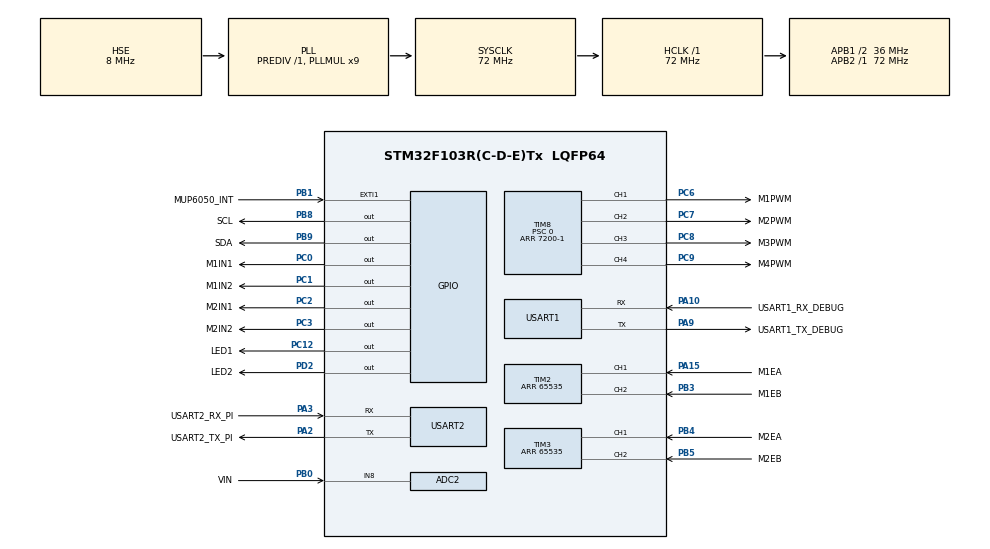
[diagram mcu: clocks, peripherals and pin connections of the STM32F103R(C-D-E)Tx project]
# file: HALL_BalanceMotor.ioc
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ADC1.Channel-0\#ChannelRegularConversion=ADC_CHANNEL_TEMPSENSOR
ADC1.NbrOfConversionFlag=1
ADC1.Rank-0\#ChannelRegularConversion=1
ADC1.SamplingTime-0\#ChannelRegularConversion=ADC_SAMPLETIME_1CYCLE_5
ADC1.master=1
ADC2.Channel-0\#ChannelRegularConversion=ADC_CHANNEL_8
ADC2.NbrOfConversionFlag=1
ADC2.Rank-0\#ChannelRegularConversion=1
ADC2.SamplingTime-0\#ChannelRegularConversion=ADC_SAMPLETIME_1CYCLE_5
Dma.Request0=USART2_RX
Dma.USART2_RX.0.Direction=DMA_PERIPH_TO_MEMORY
Dma.USART2_RX.0.Instance=DMA1_Channel6
Dma.USART2_RX.0.MemDataAlignment=DMA_MDATAALIGN_BYTE
Dma.USART2_RX.0.MemInc=DMA_MINC_ENABLE
Dma.USART2_RX.0.Mode=DMA_CIRCULAR
Dma.USART2_RX.0.PeriphDataAlignment=DMA_PDATAALIGN_BYTE
Dma.USART2_RX.0.PeriphInc=DMA_PINC_DISABLE
Dma.USART2_RX.0.Priority=DMA_PRIORITY_HIGH
FREERTOS.BinarySemaphores01=imu_sema,Dynamic,NULL;move_sema,Dynamic,NULL
FREERTOS.HEAP_NUMBER=4
FREERTOS.Tasks01=defaultTask,0,128,StartDefaultTask,Default,NULL,Dynamic,NULL,NULL;KEY,0,128,key_task,As external,NULL,Dynamic,NULL,NULL;LED,0,128,led_task,As external,NULL,Dynamic,NULL,NULL;CMD,0,128,cmd_task,As external,NULL,Dynamic,NULL,NULL;MOVE,3,128,move_task,As external,NULL,Dynamic,NULL,NULL;VIN,0,128,vin_task,As external,NULL,Dynamic,NULL,NULL;PI,0,128,pi_task,As external,NULL,Dynamic,NULL,NULL;IMU,3,128,imu_task,As external,NULL,Dynamic,NULL,NULL;OTHER,0,128,other_task,As external,NULL,Dynamic,NULL,NULL
FREERTOS.configTOTAL_HEAP_SIZE=10000
FREERTOS.configUSE_NEWLIB_REENTRANT=0
FREERTOS.configUSE_PREEMPTION=1
FREERTOS.configUSE_TRACE_FACILITY=0
Mcu.Family=STM32F1
Mcu.Name=STM32F103R(C-D-E)Tx
Mcu.Package=LQFP64
NVIC.DMA1_Channel6_IRQn=true\:5\:0\:false\:false\:true\:true\:false\:true\:true
NVIC.PriorityGroup=NVIC_PRIORITYGROUP_4
NVIC.TIM2_IRQn=true\:5\:0\:false\:false\:true\:true\:true\:true\:true
NVIC.TIM3_IRQn=true\:5\:0\:false\:false\:true\:true\:true\:true\:true
NVIC.TIM6_IRQn=true\:15\:0\:false\:false\:true\:false\:false\:true\:true
NVIC.TIM7_IRQn=true\:7\:0\:true\:false\:true\:true\:true\:true\:true
NVIC.TimeBase=TIM6_IRQn
NVIC.TimeBaseIP=TIM6
NVIC.USART1_IRQn=true\:5\:0\:false\:false\:true\:true\:true\:true\:true
NVIC.USART2_IRQn=true\:5\:0\:false\:false\:true\:true\:true\:true\:true
PA10.GPIO_Label=USART1_RX_DEBUG
PA10.Mode=Asynchronous
PA10.Signal=USART1_RX
PA13.Mode=Serial_Wire
PA13.Signal=SYS_JTMS-SWDIO
PA14.Mode=Serial_Wire
PA14.Signal=SYS_JTCK-SWCLK
PA15.GPIO_Label=M1EA
PA15.Signal=S_TIM2_CH1_ETR
PA2.GPIO_Label=USART2_TX_PI
PA2.Mode=Asynchronous
PA2.Signal=USART2_TX
PA3.GPIO_Label=USART2_RX_PI
PA3.Mode=Asynchronous
PA3.Signal=USART2_RX
PA9.GPIO_Label=USART1_TX_DEBUG
PA9.Mode=Asynchronous
PA9.Signal=USART1_TX
PB0.GPIO_Label=VIN
PB0.Signal=ADCx_IN8
PB1.GPIO_Label=MUP6050_INT
PB1.Signal=GPXTI1
PB3.GPIO_Label=M1EB
PB3.Signal=S_TIM2_CH2
PB4.GPIO_Label=M2EA
PB4.Signal=S_TIM3_CH1
PB5.GPIO_Label=M2EB
PB5.Signal=S_TIM3_CH2
PB8.GPIO_Label=SCL
PB8.GPIO_PuPd=GPIO_PULLUP
PB8.GPIO_Speed=GPIO_SPEED_FREQ_HIGH
PB8.PinState=GPIO_PIN_SET
PB8.Signal=GPIO_Output
PB9.GPIO_Label=SDA
PB9.GPIO_PuPd=GPIO_PULLUP
PB9.GPIO_Speed=GPIO_SPEED_FREQ_HIGH
PB9.PinState=GPIO_PIN_SET
PB9.Signal=GPIO_Output
PC0.GPIO_Label=M1IN1
PC0.GPIO_Speed=GPIO_SPEED_FREQ_HIGH
PC0.PinState=GPIO_PIN_RESET
PC0.Signal=GPIO_Output
PC1.GPIO_Label=M1IN2
PC1.GPIO_ModeDefaultOutputPP=GPIO_MODE_OUTPUT_PP
PC1.GPIO_PuPd=GPIO_NOPULL
PC1.GPIO_Speed=GPIO_SPEED_FREQ_HIGH
PC1.PinState=GPIO_PIN_RESET
PC1.Signal=GPIO_Output
PC12.GPIO_Label=LED1
PC12.GPIO_Speed=GPIO_SPEED_FREQ_HIGH
PC12.PinState=GPIO_PIN_SET
PC12.Signal=GPIO_Output
PC2.GPIO_Label=M2IN1
PC2.GPIO_ModeDefaultOutputPP=GPIO_MODE_OUTPUT_PP
PC2.GPIO_PuPd=GPIO_NOPULL
PC2.GPIO_Speed=GPIO_SPEED_FREQ_HIGH
PC2.PinState=GPIO_PIN_RESET
PC2.Signal=GPIO_Output
PC3.GPIO_Label=M2IN2
PC3.GPIO_ModeDefaultOutputPP=GPIO_MODE_OUTPUT_PP
PC3.GPIO_PuPd=GPIO_NOPULL
PC3.GPIO_Speed=GPIO_SPEED_FREQ_HIGH
PC3.PinState=GPIO_PIN_RESET
PC3.Signal=GPIO_Output
PC6.GPIO_Label=M1PWM
PC6.GPIO_Speed=GPIO_SPEED_FREQ_HIGH
PC6.Signal=S_TIM8_CH1
PC7.GPIO_Label=M2PWM
PC7.GPIO_Speed=GPIO_SPEED_FREQ_HIGH
PC7.Signal=S_TIM8_CH2
PC8.GPIO_Label=M3PWM
PC8.GPIO_Speed=GPIO_SPEED_FREQ_HIGH
PC8.Signal=S_TIM8_CH3
PC9.GPIO_Label=M4PWM
PC9.GPIO_Speed=GPIO_SPEED_FREQ_HIGH
PC9.Signal=S_TIM8_CH4
PD0-OSC_IN.Mode=HSE-External-Oscillator
PD0-OSC_IN.Signal=RCC_OSC_IN
PD1-OSC_OUT.Mode=HSE-External-Oscillator
PD1-OSC_OUT.Signal=RCC_OSC_OUT
PD2.GPIO_Label=LED2
PD2.GPIO_Speed=GPIO_SPEED_FREQ_HIGH
PD2.PinState=GPIO_PIN_SET
PD2.Signal=GPIO_Output
ProjectManager.HeapSize=0x200
ProjectManager.StackSize=0x400
ProjectManager.TargetToolchain=MDK-ARM V5.32
RCC.ADCPresc=RCC_ADCPCLK2_DIV6
RCC.AHBFreq_Value=72000000
RCC.APB1CLKDivider=RCC_HCLK_DIV2
RCC.APB1Freq_Value=36000000
RCC.APB1TimFreq_Value=72000000
RCC.APB2Freq_Value=72000000
RCC.APB2TimFreq_Value=72000000
RCC.HCLKFreq_Value=72000000
RCC.PLLMUL=RCC_PLL_MUL9
RCC.PLLSourceVirtual=RCC_PLLSOURCE_HSE
RCC.SYSCLKFreq_VALUE=72000000
RCC.SYSCLKSource=RCC_SYSCLKSOURCE_PLLCLK
RCC.USBFreq_Value=72000000
SH.ADCx_IN8.0=ADC2_IN8,IN8
SH.S_TIM2_CH1_ETR.0=TIM2_CH1,Encoder_Interface
SH.S_TIM2_CH2.0=TIM2_CH2,Encoder_Interface
SH.S_TIM3_CH1.0=TIM3_CH1,Encoder_Interface
SH.S_TIM3_CH2.0=TIM3_CH2,Encoder_Interface
SH.S_TIM8_CH1.0=TIM8_CH1,PWM Generation1 CH1
SH.S_TIM8_CH2.0=TIM8_CH2,PWM Generation2 CH2
SH.S_TIM8_CH3.0=TIM8_CH3,PWM Generation3 CH3
SH.S_TIM8_CH4.0=TIM8_CH4,PWM Generation4 CH4
TIM2.ClockDivision=TIM_CLOCKDIVISION_DIV1
TIM2.EncoderMode=TIM_ENCODERMODE_TI12
TIM2.IC1Filter=6
TIM2.IC1Prescaler=TIM_ICPSC_DIV1
TIM2.IC2Filter=6
TIM2.IC2Prescaler=TIM_ICPSC_DIV1
TIM2.Period=65535
TIM3.ClockDivision=TIM_CLOCKDIVISION_DIV1
TIM3.EncoderMode=TIM_ENCODERMODE_TI12
TIM3.IC1Filter=6
TIM3.IC1Polarity=TIM_ICPOLARITY_RISING
TIM3.IC1Prescaler=TIM_ICPSC_DIV1
TIM3.IC2Filter=6
TIM3.Period=65535
TIM7.Period=500-1
TIM7.Prescaler=72-1
TIM8.Channel-PWM\ Generation1\ CH1=TIM_CHANNEL_1
TIM8.Channel-PWM\ Generation2\ CH2=TIM_CHANNEL_2
TIM8.Channel-PWM\ Generation3\ CH3=TIM_CHANNEL_3
TIM8.Channel-PWM\ Generation4\ CH4=TIM_CHANNEL_4
TIM8.Period=7200-1
TIM8.Prescaler=0
USART1.VirtualMode=VM_ASYNC
USART2.VirtualMode=VM_ASYNC
VP_ADC1_TempSens_Input.Mode=IN-TempSens
VP_ADC1_Vref_Input.Mode=IN-Vrefint
VP_FREERTOS_VS_CMSIS_V1.Mode=CMSIS_V1
VP_SYS_VS_tim6.Mode=TIM6
VP_TIM7_VS_ClockSourceINT.Mode=Enable_Timer
board=custom

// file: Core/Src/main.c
/* USER CODE BEGIN Header */
/**
  ******************************************************************************
  * @file           : main.c
  * @brief          : Main program body
  ******************************************************************************
  * @attention
  *
  * Copyright (c) 2024 STMicroelectronics.
  * All rights reserved.
  *
  * This software is licensed under terms that can be found in the LICENSE file
  * in the root directory of this software component.
  * If no LICENSE file comes with this software, it is provided AS-IS.
  *
  ******************************************************************************
  */
/* USER CODE END Header */
#include "main.h"
#include "cmsis_os.h"
#include "adc.h"
#include "dma.h"
#include "tim.h"
#include "usart.h"
#include "gpio.h"

/* USER CODE BEGIN Includes */
#include "init_task.h"
#define LOG_TAG "MAIN"
#include "bsp_log.h"

/* USER CODE END Includes */

void SystemClock_Config(void);
void MX_FREERTOS_Init(void);

int main(void)
{

  /* MCU Configuration--------------------------------------------------------*/

  /* Reset of all peripherals, Initializes the Flash interface and the Systick. */
  HAL_Init();

  /* Configure the system clock */
  SystemClock_Config();

  /* Initialize all configured peripherals */
  MX_GPIO_Init();
  MX_DMA_Init();
  MX_TIM2_Init();
  MX_TIM3_Init();
  MX_TIM8_Init();
  MX_USART1_UART_Init();
  MX_ADC1_Init();
  MX_ADC2_Init();
  MX_USART2_UART_Init();
  MX_TIM7_Init();
  /* USER CODE BEGIN 2 */
  Init_Task();
  /* USER CODE END 2 */

  /* Call init function for freertos objects (in freertos.c) */
  MX_FREERTOS_Init();

  /* Start scheduler */
  osKernelStart();

  /* We should never get here as control is now taken by the scheduler */
  /* Infinite loop */
  while (1)
  {

  }
}

void SystemClock_Config(void)
{
  RCC_OscInitTypeDef RCC_OscInitStruct = {0};
  RCC_ClkInitTypeDef RCC_ClkInitStruct = {0};
  RCC_PeriphCLKInitTypeDef PeriphClkInit = {0};

  /** Initializes the RCC Oscillators according to the specified parameters
  * in the RCC_OscInitTypeDef structure.
  */
  RCC_OscInitStruct.OscillatorType = RCC_OSCILLATORTYPE_HSE;
  RCC_OscInitStruct.HSEState = RCC_HSE_ON;
  RCC_OscInitStruct.HSEPredivValue = RCC_HSE_PREDIV_DIV1;
  RCC_OscInitStruct.HSIState = RCC_HSI_ON;
  RCC_OscInitStruct.PLL.PLLState = RCC_PLL_ON;
  RCC_OscInitStruct.PLL.PLLSource = RCC_PLLSOURCE_HSE;
  RCC_OscInitStruct.PLL.PLLMUL = RCC_PLL_MUL9;
  if (HAL_RCC_OscConfig(&RCC_OscInitStruct) != HAL_OK)
  {
    Error_Handler();
  }

  /** Initializes the CPU, AHB and APB buses clocks
  */
  RCC_ClkInitStruct.ClockType = RCC_CLOCKTYPE_HCLK|RCC_CLOCKTYPE_SYSCLK
                              |RCC_CLOCKTYPE_PCLK1|RCC_CLOCKTYPE_PCLK2;
  RCC_ClkInitStruct.SYSCLKSource = RCC_SYSCLKSOURCE_PLLCLK;
  RCC_ClkInitStruct.AHBCLKDivider = RCC_SYSCLK_DIV1;
  RCC_ClkInitStruct.APB1CLKDivider = RCC_HCLK_DIV2;
  RCC_ClkInitStruct.APB2CLKDivider = RCC_HCLK_DIV1;

  if (HAL_RCC_ClockConfig(&RCC_ClkInitStruct, FLASH_LATENCY_2) != HAL_OK)
  {
    Error_Handler();
  }
  PeriphClkInit.PeriphClockSelection = RCC_PERIPHCLK_ADC;
  PeriphClkInit.AdcClockSelection = RCC_ADCPCLK2_DIV6;
  if (HAL_RCCEx_PeriphCLKConfig(&PeriphClkInit) != HAL_OK)
  {
    Error_Handler();
  }
}

void HAL_TIM_PeriodElapsedCallback(TIM_HandleTypeDef *htim)
{
  if (htim->Instance == TIM6) {
    HAL_IncTick();
  }
  /* USER CODE BEGIN Callback 1 */
 if (htim->Instance == TIM7) {
     timx_updata_callback(htim);
 }
  /* USER CODE END Callback 1 */
}

void Error_Handler(void)
{
  __disable_irq();
  while (1)
  {
  }
}

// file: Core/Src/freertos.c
/* USER CODE BEGIN Header */
/**
  ******************************************************************************
  * File Name          : freertos.c
  * Description        : Code for freertos applications
  ******************************************************************************
  * @attention
  *
  * Copyright (c) 2024 STMicroelectronics.
  * All rights reserved.
  *
  * This software is licensed under terms that can be found in the LICENSE file
  * in the root directory of this software component.
  * If no LICENSE file comes with this software, it is provided AS-IS.
  *
  ******************************************************************************
  */
/* USER CODE END Header */

#include "FreeRTOS.h"
#include "task.h"
#include "main.h"
#include "cmsis_os.h"

osThreadId defaultTaskHandle;
osThreadId KEYHandle;
osThreadId LEDHandle;
osThreadId CMDHandle;
osThreadId MOVEHandle;
osThreadId VINHandle;
osThreadId PIHandle;
osThreadId IMUHandle;
osThreadId OTHERHandle;
osSemaphoreId imu_semaHandle;
osSemaphoreId move_semaHandle;

void StartDefaultTask(void const * argument);
extern void key_task(void const * argument);
extern void led_task(void const * argument);
extern void cmd_task(void const * argument);
extern void move_task(void const * argument);
extern void vin_task(void const * argument);
extern void pi_task(void const * argument);
extern void imu_task(void const * argument);
extern void other_task(void const * argument);

void MX_FREERTOS_Init(void); /* (MISRA C 2004 rule 8.1) */

/* GetIdleTaskMemory prototype (linked to static allocation support) */
void vApplicationGetIdleTaskMemory( StaticTask_t **ppxIdleTaskTCBBuffer, StackType_t **ppxIdleTaskStackBuffer, uint32_t *pulIdleTaskStackSize );

/* USER CODE BEGIN GET_IDLE_TASK_MEMORY */
static StaticTask_t xIdleTaskTCBBuffer;
static StackType_t xIdleStack[configMINIMAL_STACK_SIZE];

void vApplicationGetIdleTaskMemory( StaticTask_t **ppxIdleTaskTCBBuffer, StackType_t **ppxIdleTaskStackBuffer, uint32_t *pulIdleTaskStackSize )
{
  *ppxIdleTaskTCBBuffer = &xIdleTaskTCBBuffer;
  *ppxIdleTaskStackBuffer = &xIdleStack[0];
  *pulIdleTaskStackSize = configMINIMAL_STACK_SIZE;
  /* place for user code */
}
/* USER CODE END GET_IDLE_TASK_MEMORY */

void MX_FREERTOS_Init(void) {

  /* Create the semaphores(s) */
  /* definition and creation of imu_sema */
  osSemaphoreDef(imu_sema);
  imu_semaHandle = osSemaphoreCreate(osSemaphore(imu_sema), 1);

  /* definition and creation of move_sema */
  osSemaphoreDef(move_sema);
  move_semaHandle = osSemaphoreCreate(osSemaphore(move_sema), 1);

  /* Create the thread(s) */
  /* definition and creation of defaultTask */
  osThreadDef(defaultTask, StartDefaultTask, osPriorityNormal, 0, 128);
  defaultTaskHandle = osThreadCreate(osThread(defaultTask), NULL);

  /* definition and creation of KEY */
  osThreadDef(KEY, key_task, osPriorityNormal, 0, 128);
  KEYHandle = osThreadCreate(osThread(KEY), NULL);

  /* definition and creation of LED */
  osThreadDef(LED, led_task, osPriorityNormal, 0, 128);
  LEDHandle = osThreadCreate(osThread(LED), NULL);

  /* definition and creation of CMD */
  osThreadDef(CMD, cmd_task, osPriorityNormal, 0, 128);
  CMDHandle = osThreadCreate(osThread(CMD), NULL);

  /* definition and creation of MOVE */
  osThreadDef(MOVE, move_task, osPriorityRealtime, 0, 128);
  MOVEHandle = osThreadCreate(osThread(MOVE), NULL);

  /* definition and creation of VIN */
  osThreadDef(VIN, vin_task, osPriorityNormal, 0, 128);
  VINHandle = osThreadCreate(osThread(VIN), NULL);

  /* definition and creation of PI */
  osThreadDef(PI, pi_task, osPriorityNormal, 0, 128);
  PIHandle = osThreadCreate(osThread(PI), NULL);

  /* definition and creation of IMU */
  osThreadDef(IMU, imu_task, osPriorityRealtime, 0, 128);
  IMUHandle = osThreadCreate(osThread(IMU), NULL);

  /* definition and creation of OTHER */
  osThreadDef(OTHER, other_task, osPriorityNormal, 0, 128);
  OTHERHandle = osThreadCreate(osThread(OTHER), NULL);

}

void StartDefaultTask(void const * argument)
{
  /* USER CODE BEGIN StartDefaultTask */
  /* Infinite loop */
  for(;;)
  {
    osDelay(1000);
  }
  /* USER CODE END StartDefaultTask */
}
